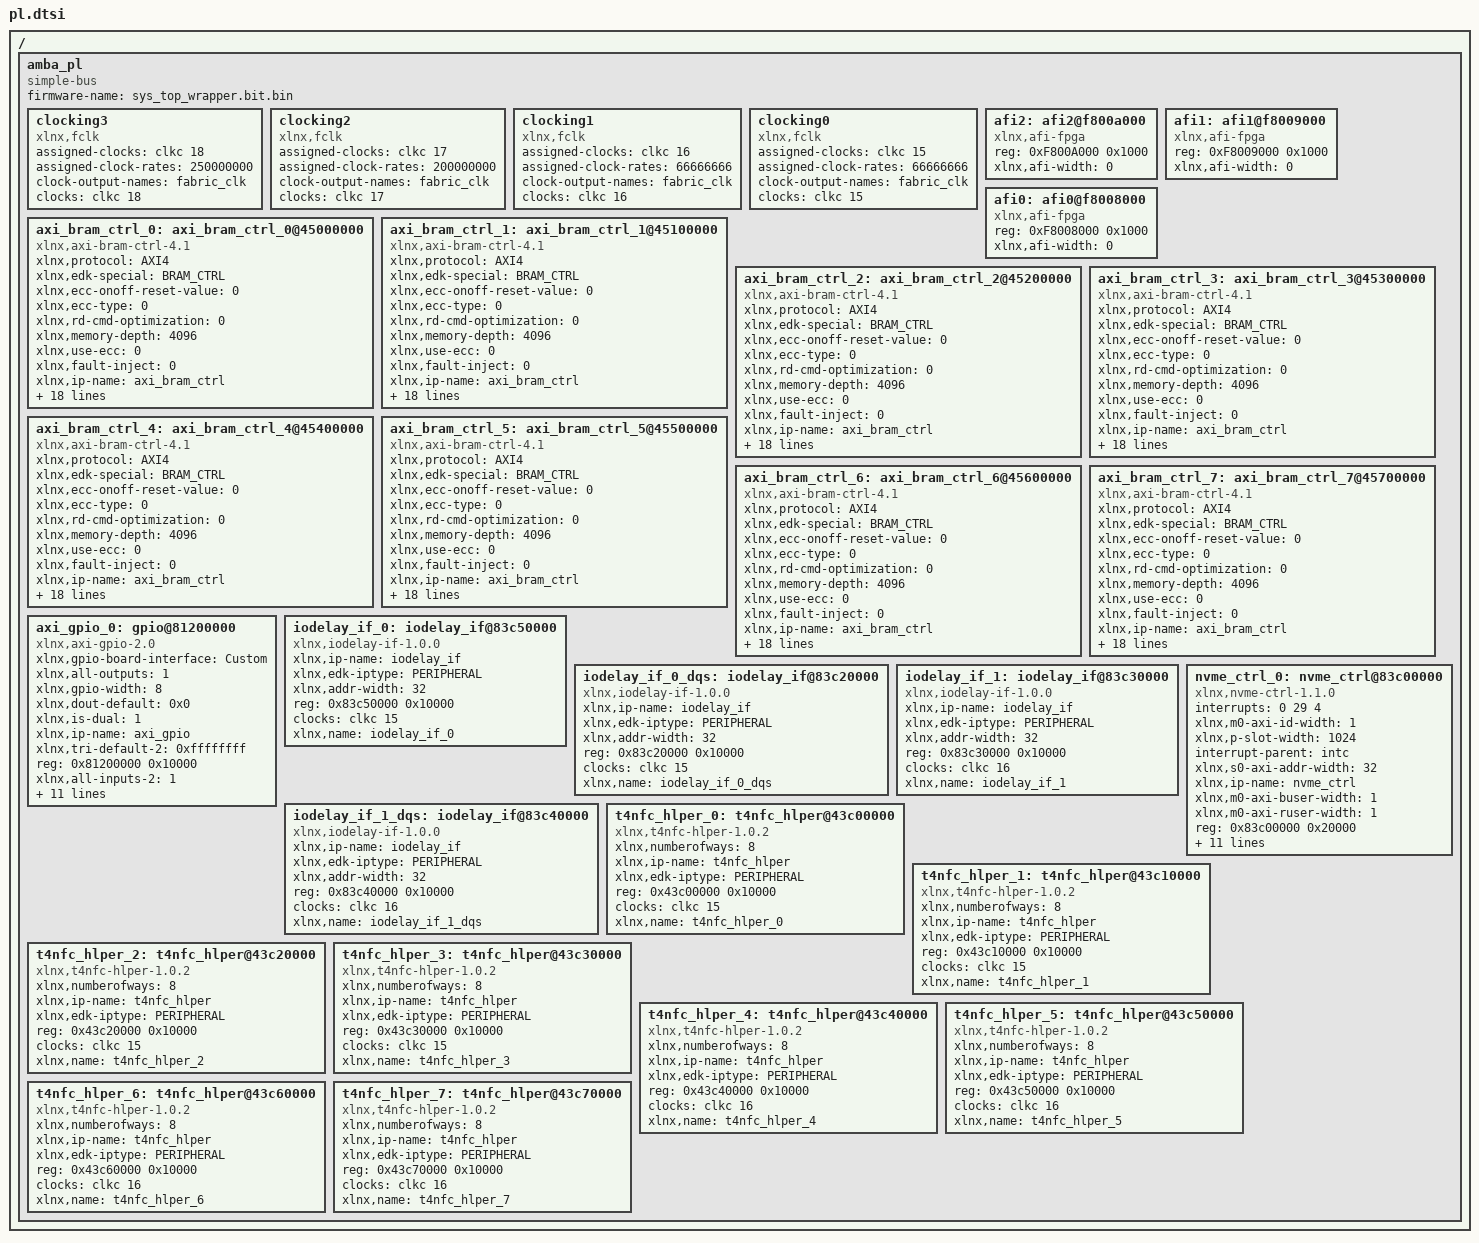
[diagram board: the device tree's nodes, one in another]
/ {
	amba_pl: amba_pl {
		ranges;
		compatible = "simple-bus";
		#address-cells = <1>;
		#size-cells = <1>;
		firmware-name = "sys_top_wrapper.bit.bin";
		clocking3: clocking3 {
			compatible = "xlnx,fclk";
			assigned-clocks = <&clkc 18>;
			assigned-clock-rates = <250000000>;
			#clock-cells = <0>;
			clock-output-names = "fabric_clk";
			clocks = <&clkc 18>;
		};
		clocking2: clocking2 {
			compatible = "xlnx,fclk";
			assigned-clocks = <&clkc 17>;
			assigned-clock-rates = <200000000>;
			#clock-cells = <0>;
			clock-output-names = "fabric_clk";
			clocks = <&clkc 17>;
		};
		clocking1: clocking1 {
			compatible = "xlnx,fclk";
			assigned-clocks = <&clkc 16>;
			assigned-clock-rates = <66666666>;
			#clock-cells = <0>;
			clock-output-names = "fabric_clk";
			clocks = <&clkc 16>;
		};
		clocking0: clocking0 {
			compatible = "xlnx,fclk";
			assigned-clocks = <&clkc 15>;
			assigned-clock-rates = <66666666>;
			#clock-cells = <0>;
			clock-output-names = "fabric_clk";
			clocks = <&clkc 15>;
		};
		afi2: afi2@f800a000 {
			status = "okay";
			compatible = "xlnx,afi-fpga";
			#address-cells = <1>;
			reg = <0xF800A000 0x1000>;
			#size-cells = <0>;
			xlnx,afi-width = <0>;
		};
		afi1: afi1@f8009000 {
			status = "okay";
			compatible = "xlnx,afi-fpga";
			#address-cells = <1>;
			reg = <0xF8009000 0x1000>;
			#size-cells = <0>;
			xlnx,afi-width = <0>;
		};
		afi0: afi0@f8008000 {
			status = "okay";
			compatible = "xlnx,afi-fpga";
			#address-cells = <1>;
			reg = <0xF8008000 0x1000>;
			#size-cells = <0>;
			xlnx,afi-width = <0>;
		};
		axi_bram_ctrl_0: axi_bram_ctrl_0@45000000 {
			xlnx,protocol = "AXI4";
			xlnx,edk-special = "BRAM_CTRL";
			compatible = "xlnx,axi-bram-ctrl-4.1" , "xlnx,axi-bram-ctrl";
			xlnx,ecc-onoff-reset-value = <0>;
			xlnx,ecc-type = <0>;
			xlnx,rd-cmd-optimization = <0>;
			xlnx,memory-depth = <4096>;
			xlnx,use-ecc = <0>;
			xlnx,fault-inject = <0>;
			xlnx,ip-name = "axi_bram_ctrl";
			reg = <0x45000000 0x4000>;
			xlnx,bmg-instance = "EXTERNAL";
			clocks = <&clkc 15>;
			xlnx,s-axi-ctrl-addr-width = <32>;
			xlnx,read-latency = <1>;
			xlnx,id-width = <12>;
			xlnx,s-axi-supports-narrow-burst = <0>;
			xlnx,supports-narrow-burst = <0>;
			xlnx,single-port-bram = <1>;
			xlnx,ecc = <0>;
			xlnx,edk-iptype = "PERIPHERAL";
			status = "okay";
			clock-names = "s_axi_aclk";
			xlnx,data-width = <32>;
			xlnx,bram-addr-width = <12>;
			xlnx,bram-inst-mode = "EXTERNAL";
			xlnx,s-axi-ctrl-data-width = <32>;
			xlnx,mem-depth = <4096>;
			xlnx,s-axi-id-width = <12>;
			xlnx,name = "axi_bram_ctrl_0";
		};
		axi_bram_ctrl_1: axi_bram_ctrl_1@45100000 {
			xlnx,protocol = "AXI4";
			xlnx,edk-special = "BRAM_CTRL";
			compatible = "xlnx,axi-bram-ctrl-4.1" , "xlnx,axi-bram-ctrl";
			xlnx,ecc-onoff-reset-value = <0>;
			xlnx,ecc-type = <0>;
			xlnx,rd-cmd-optimization = <0>;
			xlnx,memory-depth = <4096>;
			xlnx,use-ecc = <0>;
			xlnx,fault-inject = <0>;
			xlnx,ip-name = "axi_bram_ctrl";
			reg = <0x45100000 0x4000>;
			xlnx,bmg-instance = "EXTERNAL";
			clocks = <&clkc 15>;
			xlnx,s-axi-ctrl-addr-width = <32>;
			xlnx,read-latency = <1>;
			xlnx,id-width = <12>;
			xlnx,s-axi-supports-narrow-burst = <0>;
			xlnx,supports-narrow-burst = <0>;
			xlnx,single-port-bram = <1>;
			xlnx,ecc = <0>;
			xlnx,edk-iptype = "PERIPHERAL";
			status = "okay";
			clock-names = "s_axi_aclk";
			xlnx,data-width = <32>;
			xlnx,bram-addr-width = <12>;
			xlnx,bram-inst-mode = "EXTERNAL";
			xlnx,s-axi-ctrl-data-width = <32>;
			xlnx,mem-depth = <4096>;
			xlnx,s-axi-id-width = <12>;
			xlnx,name = "axi_bram_ctrl_1";
		};
		axi_bram_ctrl_2: axi_bram_ctrl_2@45200000 {
			xlnx,protocol = "AXI4";
			xlnx,edk-special = "BRAM_CTRL";
			compatible = "xlnx,axi-bram-ctrl-4.1" , "xlnx,axi-bram-ctrl";
			xlnx,ecc-onoff-reset-value = <0>;
			xlnx,ecc-type = <0>;
			xlnx,rd-cmd-optimization = <0>;
			xlnx,memory-depth = <4096>;
			xlnx,use-ecc = <0>;
			xlnx,fault-inject = <0>;
			xlnx,ip-name = "axi_bram_ctrl";
			reg = <0x45200000 0x4000>;
			xlnx,bmg-instance = "EXTERNAL";
			clocks = <&clkc 15>;
			xlnx,s-axi-ctrl-addr-width = <32>;
			xlnx,read-latency = <1>;
			xlnx,id-width = <12>;
			xlnx,s-axi-supports-narrow-burst = <0>;
			xlnx,supports-narrow-burst = <0>;
			xlnx,single-port-bram = <1>;
			xlnx,ecc = <0>;
			xlnx,edk-iptype = "PERIPHERAL";
			status = "okay";
			clock-names = "s_axi_aclk";
			xlnx,data-width = <32>;
			xlnx,bram-addr-width = <12>;
			xlnx,bram-inst-mode = "EXTERNAL";
			xlnx,s-axi-ctrl-data-width = <32>;
			xlnx,mem-depth = <4096>;
			xlnx,s-axi-id-width = <12>;
			xlnx,name = "axi_bram_ctrl_2";
		};
		axi_bram_ctrl_3: axi_bram_ctrl_3@45300000 {
			xlnx,protocol = "AXI4";
			xlnx,edk-special = "BRAM_CTRL";
			compatible = "xlnx,axi-bram-ctrl-4.1" , "xlnx,axi-bram-ctrl";
			xlnx,ecc-onoff-reset-value = <0>;
			xlnx,ecc-type = <0>;
			xlnx,rd-cmd-optimization = <0>;
			xlnx,memory-depth = <4096>;
			xlnx,use-ecc = <0>;
			xlnx,fault-inject = <0>;
			xlnx,ip-name = "axi_bram_ctrl";
			reg = <0x45300000 0x4000>;
			xlnx,bmg-instance = "EXTERNAL";
			clocks = <&clkc 15>;
			xlnx,s-axi-ctrl-addr-width = <32>;
			xlnx,read-latency = <1>;
			xlnx,id-width = <12>;
			xlnx,s-axi-supports-narrow-burst = <0>;
			xlnx,supports-narrow-burst = <0>;
			xlnx,single-port-bram = <1>;
			xlnx,ecc = <0>;
			xlnx,edk-iptype = "PERIPHERAL";
			status = "okay";
			clock-names = "s_axi_aclk";
			xlnx,data-width = <32>;
			xlnx,bram-addr-width = <12>;
			xlnx,bram-inst-mode = "EXTERNAL";
			xlnx,s-axi-ctrl-data-width = <32>;
			xlnx,mem-depth = <4096>;
			xlnx,s-axi-id-width = <12>;
			xlnx,name = "axi_bram_ctrl_3";
		};
		axi_bram_ctrl_4: axi_bram_ctrl_4@45400000 {
			xlnx,protocol = "AXI4";
			xlnx,edk-special = "BRAM_CTRL";
			compatible = "xlnx,axi-bram-ctrl-4.1" , "xlnx,axi-bram-ctrl";
			xlnx,ecc-onoff-reset-value = <0>;
			xlnx,ecc-type = <0>;
			xlnx,rd-cmd-optimization = <0>;
			xlnx,memory-depth = <4096>;
			xlnx,use-ecc = <0>;
			xlnx,fault-inject = <0>;
			xlnx,ip-name = "axi_bram_ctrl";
			reg = <0x45400000 0x4000>;
			xlnx,bmg-instance = "EXTERNAL";
			clocks = <&clkc 16>;
			xlnx,s-axi-ctrl-addr-width = <32>;
			xlnx,read-latency = <1>;
			xlnx,id-width = <12>;
			xlnx,s-axi-supports-narrow-burst = <0>;
			xlnx,supports-narrow-burst = <0>;
			xlnx,single-port-bram = <1>;
			xlnx,ecc = <0>;
			xlnx,edk-iptype = "PERIPHERAL";
			status = "okay";
			clock-names = "s_axi_aclk";
			xlnx,data-width = <32>;
			xlnx,bram-addr-width = <12>;
			xlnx,bram-inst-mode = "EXTERNAL";
			xlnx,s-axi-ctrl-data-width = <32>;
			xlnx,mem-depth = <4096>;
			xlnx,s-axi-id-width = <12>;
			xlnx,name = "axi_bram_ctrl_4";
		};
		axi_bram_ctrl_5: axi_bram_ctrl_5@45500000 {
			xlnx,protocol = "AXI4";
			xlnx,edk-special = "BRAM_CTRL";
			compatible = "xlnx,axi-bram-ctrl-4.1" , "xlnx,axi-bram-ctrl";
			xlnx,ecc-onoff-reset-value = <0>;
			xlnx,ecc-type = <0>;
			xlnx,rd-cmd-optimization = <0>;
			xlnx,memory-depth = <4096>;
			xlnx,use-ecc = <0>;
			xlnx,fault-inject = <0>;
			xlnx,ip-name = "axi_bram_ctrl";
			reg = <0x45500000 0x4000>;
			xlnx,bmg-instance = "EXTERNAL";
			clocks = <&clkc 16>;
			xlnx,s-axi-ctrl-addr-width = <32>;
			xlnx,read-latency = <1>;
			xlnx,id-width = <12>;
			xlnx,s-axi-supports-narrow-burst = <0>;
			xlnx,supports-narrow-burst = <0>;
			xlnx,single-port-bram = <1>;
			xlnx,ecc = <0>;
			xlnx,edk-iptype = "PERIPHERAL";
			status = "okay";
			clock-names = "s_axi_aclk";
			xlnx,data-width = <32>;
			xlnx,bram-addr-width = <12>;
			xlnx,bram-inst-mode = "EXTERNAL";
			xlnx,s-axi-ctrl-data-width = <32>;
			xlnx,mem-depth = <4096>;
			xlnx,s-axi-id-width = <12>;
			xlnx,name = "axi_bram_ctrl_5";
		};
		axi_bram_ctrl_6: axi_bram_ctrl_6@45600000 {
			xlnx,protocol = "AXI4";
			xlnx,edk-special = "BRAM_CTRL";
			compatible = "xlnx,axi-bram-ctrl-4.1" , "xlnx,axi-bram-ctrl";
			xlnx,ecc-onoff-reset-value = <0>;
			xlnx,ecc-type = <0>;
			xlnx,rd-cmd-optimization = <0>;
			xlnx,memory-depth = <4096>;
			xlnx,use-ecc = <0>;
			xlnx,fault-inject = <0>;
			xlnx,ip-name = "axi_bram_ctrl";
			reg = <0x45600000 0x4000>;
			xlnx,bmg-instance = "EXTERNAL";
			clocks = <&clkc 16>;
			xlnx,s-axi-ctrl-addr-width = <32>;
			xlnx,read-latency = <1>;
			xlnx,id-width = <12>;
			xlnx,s-axi-supports-narrow-burst = <0>;
			xlnx,supports-narrow-burst = <0>;
			xlnx,single-port-bram = <1>;
			xlnx,ecc = <0>;
			xlnx,edk-iptype = "PERIPHERAL";
			status = "okay";
			clock-names = "s_axi_aclk";
			xlnx,data-width = <32>;
			xlnx,bram-addr-width = <12>;
			xlnx,bram-inst-mode = "EXTERNAL";
			xlnx,s-axi-ctrl-data-width = <32>;
			xlnx,mem-depth = <4096>;
			xlnx,s-axi-id-width = <12>;
			xlnx,name = "axi_bram_ctrl_6";
		};
		axi_bram_ctrl_7: axi_bram_ctrl_7@45700000 {
			xlnx,protocol = "AXI4";
			xlnx,edk-special = "BRAM_CTRL";
			compatible = "xlnx,axi-bram-ctrl-4.1" , "xlnx,axi-bram-ctrl";
			xlnx,ecc-onoff-reset-value = <0>;
			xlnx,ecc-type = <0>;
			xlnx,rd-cmd-optimization = <0>;
			xlnx,memory-depth = <4096>;
			xlnx,use-ecc = <0>;
			xlnx,fault-inject = <0>;
			xlnx,ip-name = "axi_bram_ctrl";
			reg = <0x45700000 0x4000>;
			xlnx,bmg-instance = "EXTERNAL";
			clocks = <&clkc 16>;
			xlnx,s-axi-ctrl-addr-width = <32>;
			xlnx,read-latency = <1>;
			xlnx,id-width = <12>;
			xlnx,s-axi-supports-narrow-burst = <0>;
			xlnx,supports-narrow-burst = <0>;
			xlnx,single-port-bram = <1>;
			xlnx,ecc = <0>;
			xlnx,edk-iptype = "PERIPHERAL";
			status = "okay";
			clock-names = "s_axi_aclk";
			xlnx,data-width = <32>;
			xlnx,bram-addr-width = <12>;
			xlnx,bram-inst-mode = "EXTERNAL";
			xlnx,s-axi-ctrl-data-width = <32>;
			xlnx,mem-depth = <4096>;
			xlnx,s-axi-id-width = <12>;
			xlnx,name = "axi_bram_ctrl_7";
		};
		axi_gpio_0: gpio@81200000 {
			xlnx,gpio-board-interface = "Custom";
			compatible = "xlnx,axi-gpio-2.0" , "xlnx,xps-gpio-1.00.a";
			xlnx,all-outputs = <1>;
			#gpio-cells = <2>;
			xlnx,gpio-width = <8>;
			xlnx,dout-default = <0x0>;
			xlnx,is-dual = <1>;
			xlnx,ip-name = "axi_gpio";
			xlnx,tri-default-2 = <0xffffffff>;
			reg = <0x81200000 0x10000>;
			xlnx,all-inputs-2 = <1>;
			clocks = <&clkc 17>;
			xlnx,all-outputs-2 = <0>;
			gpio-controller;
			xlnx,interrupt-present = <0>;
			xlnx,gpio2-board-interface = "Custom";
			xlnx,edk-iptype = "PERIPHERAL";
			xlnx,dout-default-2 = <0x0>;
			status = "okay";
			xlnx,gpio2-width = <8>;
			clock-names = "s_axi_aclk";
			xlnx,tri-default = <0xffffffff>;
			xlnx,name = "axi_gpio_0";
			xlnx,all-inputs = <0>;
		};
		iodelay_if_0: iodelay_if@83c50000 {
			compatible = "xlnx,iodelay-if-1.0.0";
			status = "okay";
			clock-names = "sys__clk";
			xlnx,ip-name = "iodelay_if";
			xlnx,edk-iptype = "PERIPHERAL";
			xlnx,addr-width = <32>;
			reg = <0x83c50000 0x10000>;
			clocks = <&clkc 15>;
			xlnx,name = "iodelay_if_0";
		};
		iodelay_if_0_dqs: iodelay_if@83c20000 {
			compatible = "xlnx,iodelay-if-1.0.0";
			status = "okay";
			clock-names = "sys__clk";
			xlnx,ip-name = "iodelay_if";
			xlnx,edk-iptype = "PERIPHERAL";
			xlnx,addr-width = <32>;
			reg = <0x83c20000 0x10000>;
			clocks = <&clkc 15>;
			xlnx,name = "iodelay_if_0_dqs";
		};
		iodelay_if_1: iodelay_if@83c30000 {
			compatible = "xlnx,iodelay-if-1.0.0";
			status = "okay";
			clock-names = "sys__clk";
			xlnx,ip-name = "iodelay_if";
			xlnx,edk-iptype = "PERIPHERAL";
			xlnx,addr-width = <32>;
			reg = <0x83c30000 0x10000>;
			clocks = <&clkc 16>;
			xlnx,name = "iodelay_if_1";
		};
		iodelay_if_1_dqs: iodelay_if@83c40000 {
			compatible = "xlnx,iodelay-if-1.0.0";
			status = "okay";
			clock-names = "sys__clk";
			xlnx,ip-name = "iodelay_if";
			xlnx,edk-iptype = "PERIPHERAL";
			xlnx,addr-width = <32>;
			reg = <0x83c40000 0x10000>;
			clocks = <&clkc 16>;
			xlnx,name = "iodelay_if_1_dqs";
		};
		nvme_ctrl_0: nvme_ctrl@83c00000 {
			interrupts = < 0 29 4 >;
			compatible = "xlnx,nvme-ctrl-1.1.0";
			xlnx,m0-axi-id-width = <1>;
			xlnx,p-slot-width = <1024>;
			interrupt-parent = <&intc>;
			xlnx,s0-axi-addr-width = <32>;
			xlnx,ip-name = "nvme_ctrl";
			xlnx,m0-axi-buser-width = <1>;
			xlnx,m0-axi-ruser-width = <1>;
			reg = <0x83c00000 0x20000>;
			xlnx,m0-axi-aruser-width = <1>;
			xlnx,m0-axi-data-width = <64>;
			clocks = <&clkc 18>, <&clkc 17>;
			xlnx,edk-iptype = "PERIPHERAL";
			xlnx,m0-axi-wuser-width = <1>;
			xlnx,p-slot-tag-width = <10>;
			xlnx,pcie-data-width = <128>;
			xlnx,m0-axi-awuser-width = <1>;
			xlnx,s0-axi-data-width = <32>;
			status = "okay";
			clock-names = "m0_axi_aclk" , "s0_axi_aclk";
			interrupt-names = "dev_irq_assert";
			xlnx,name = "nvme_ctrl_0";
			xlnx,m0-axi-addr-width = <32>;
		};
		t4nfc_hlper_0: t4nfc_hlper@43c00000 {
			xlnx,numberofways = <8>;
			compatible = "xlnx,t4nfc-hlper-1.0.2";
			status = "okay";
			clock-names = "iClock";
			xlnx,ip-name = "t4nfc_hlper";
			xlnx,edk-iptype = "PERIPHERAL";
			reg = <0x43c00000 0x10000>;
			clocks = <&clkc 15>;
			xlnx,name = "t4nfc_hlper_0";
		};
		t4nfc_hlper_1: t4nfc_hlper@43c10000 {
			xlnx,numberofways = <8>;
			compatible = "xlnx,t4nfc-hlper-1.0.2";
			status = "okay";
			clock-names = "iClock";
			xlnx,ip-name = "t4nfc_hlper";
			xlnx,edk-iptype = "PERIPHERAL";
			reg = <0x43c10000 0x10000>;
			clocks = <&clkc 15>;
			xlnx,name = "t4nfc_hlper_1";
		};
		t4nfc_hlper_2: t4nfc_hlper@43c20000 {
			xlnx,numberofways = <8>;
			compatible = "xlnx,t4nfc-hlper-1.0.2";
			status = "okay";
			clock-names = "iClock";
			xlnx,ip-name = "t4nfc_hlper";
			xlnx,edk-iptype = "PERIPHERAL";
			reg = <0x43c20000 0x10000>;
			clocks = <&clkc 15>;
			xlnx,name = "t4nfc_hlper_2";
		};
		t4nfc_hlper_3: t4nfc_hlper@43c30000 {
			xlnx,numberofways = <8>;
			compatible = "xlnx,t4nfc-hlper-1.0.2";
			status = "okay";
			clock-names = "iClock";
			xlnx,ip-name = "t4nfc_hlper";
			xlnx,edk-iptype = "PERIPHERAL";
			reg = <0x43c30000 0x10000>;
			clocks = <&clkc 15>;
			xlnx,name = "t4nfc_hlper_3";
		};
		t4nfc_hlper_4: t4nfc_hlper@43c40000 {
			xlnx,numberofways = <8>;
			compatible = "xlnx,t4nfc-hlper-1.0.2";
			status = "okay";
			clock-names = "iClock";
			xlnx,ip-name = "t4nfc_hlper";
			xlnx,edk-iptype = "PERIPHERAL";
			reg = <0x43c40000 0x10000>;
			clocks = <&clkc 16>;
			xlnx,name = "t4nfc_hlper_4";
		};
		t4nfc_hlper_5: t4nfc_hlper@43c50000 {
			xlnx,numberofways = <8>;
			compatible = "xlnx,t4nfc-hlper-1.0.2";
			status = "okay";
			clock-names = "iClock";
			xlnx,ip-name = "t4nfc_hlper";
			xlnx,edk-iptype = "PERIPHERAL";
			reg = <0x43c50000 0x10000>;
			clocks = <&clkc 16>;
			xlnx,name = "t4nfc_hlper_5";
		};
		t4nfc_hlper_6: t4nfc_hlper@43c60000 {
			xlnx,numberofways = <8>;
			compatible = "xlnx,t4nfc-hlper-1.0.2";
			status = "okay";
			clock-names = "iClock";
			xlnx,ip-name = "t4nfc_hlper";
			xlnx,edk-iptype = "PERIPHERAL";
			reg = <0x43c60000 0x10000>;
			clocks = <&clkc 16>;
			xlnx,name = "t4nfc_hlper_6";
		};
		t4nfc_hlper_7: t4nfc_hlper@43c70000 {
			xlnx,numberofways = <8>;
			compatible = "xlnx,t4nfc-hlper-1.0.2";
			status = "okay";
			clock-names = "iClock";
			xlnx,ip-name = "t4nfc_hlper";
			xlnx,edk-iptype = "PERIPHERAL";
			reg = <0x43c70000 0x10000>;
			clocks = <&clkc 16>;
			xlnx,name = "t4nfc_hlper_7";
		};
	};
};
